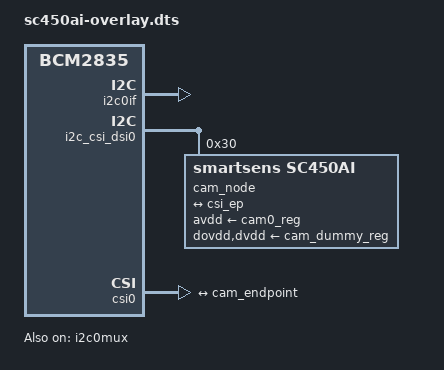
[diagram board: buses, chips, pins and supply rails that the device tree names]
/dts-v1/;
/plugin/;

/*
 * SC450AI on Raspberry Pi 5 CAM/DISP 0.
 * 4 lanes at 180 MHz by default. Pass `2lane` for the 2-lane 360 MHz table.
 */

/{
	compatible = "brcm,bcm2835";

	fragment@0 {
		target = <&i2c0if>;
		__overlay__ {
			status = "okay";
		};
	};

	fragment@1 {
		target = <&i2c0mux>;
		__overlay__ {
			status = "okay";
		};
	};

	clk_frag: fragment@2 {
		target = <&cam0_clk>;
		__overlay__ {
			status = "okay";
			clock-frequency = <27000000>;
		};
	};

	i2c_frag: fragment@3 {
		target = <&i2c_csi_dsi0>;
		__overlay__ {
			#address-cells = <1>;
			#size-cells = <0>;
			status = "okay";

			cam_node: sc450ai@30 {
				compatible = "smartsens,sc450ai";
				reg = <0x30>;
				status = "okay";

				clocks = <&cam0_clk>;
				clock-names = "xclk";

				avdd-supply = <&cam0_reg>;
				dovdd-supply = <&cam_dummy_reg>;
				dvdd-supply = <&cam_dummy_reg>;

				rotation = <0>;
				orientation = <2>;

				port {
					cam_endpoint: endpoint {
						clock-lanes = <0>;
						data-lanes = <1 2 3 4>;
						link-frequencies =
							/bits/ 64 <180000000>;
						remote-endpoint = <&csi_ep>;
					};
				};
			};
		};
	};

	csi_frag: fragment@4 {
		target = <&csi0>;
		__overlay__ {
			status = "okay";

			port {
				csi_ep: endpoint {
					remote-endpoint = <&cam_endpoint>;
					clock-lanes = <0>;
					data-lanes = <1 2 3 4>;
				};
			};
		};
	};

	fragment@5 {
		target = <&cam_endpoint>;
		__dormant__ {
			data-lanes = <1 2>;
			link-frequencies = /bits/ 64 <360000000>;
		};
	};

	fragment@6 {
		target = <&csi_ep>;
		__dormant__ {
			data-lanes = <1 2>;
		};
	};

	__overrides__ {
		2lane = <0>, "+5+6";
	};
};
